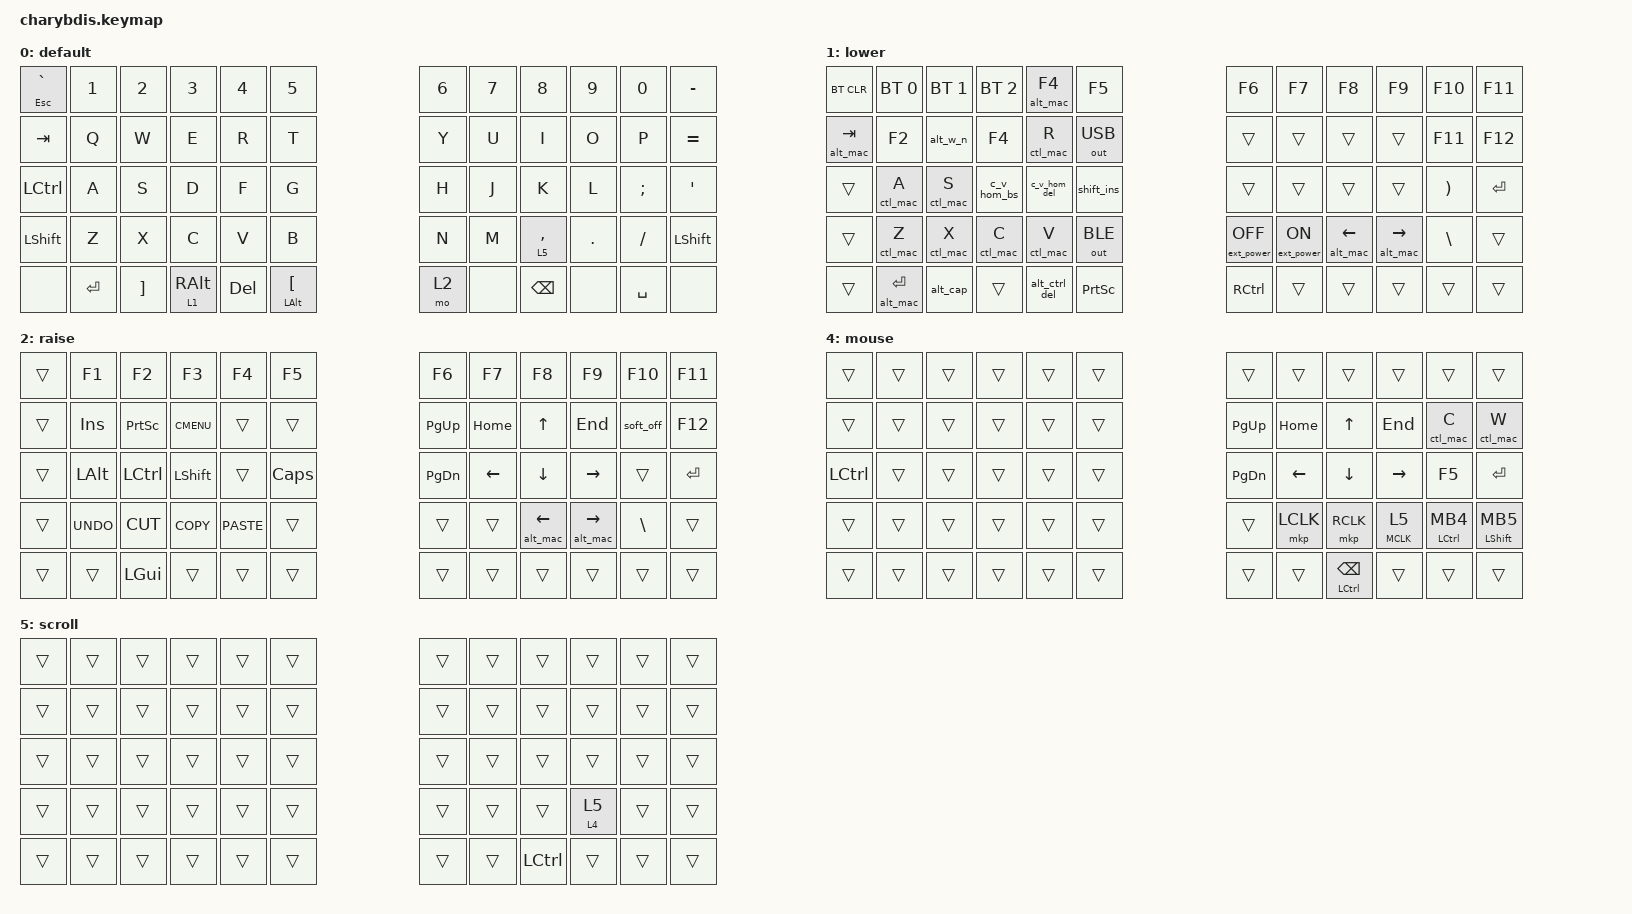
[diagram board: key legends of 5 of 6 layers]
/*
 * Copyright (c) 2020 The ZMK Contributors
 *
 * SPDX-License-Identifier: MIT
 */

#include <behaviors.dtsi>
#include <behaviors/mouse_key_press.dtsi>
#include <dt-bindings/zmk/keys.h>
#include <dt-bindings/zmk/bt.h>
#include <dt-bindings/zmk/rgb.h>
#include <dt-bindings/zmk/ext_power.h>
#include <dt-bindings/zmk/outputs.h>
#include <dt-bindings/zmk/mouse.h>

#define BASE 0
#define LOWER 1
#define RAISE 2
#define ADJUST 3
#define MOUSE 4
#define SCROLL 5

&soft_off {
    hold-time-ms = <3000>; // Only turn off it the key is held for 3 seconds or longer.
};

/ {
    macros {
        shift_ins: shift_ins {
            label = "ZM_shift_ins";
            compatible = "zmk,behavior-macro";
            #binding-cells = <0>;
            bindings
                = <&macro_press &kp LSHFT>
                , <&macro_tap &kp INS>
                , <&macro_release &kp LSHFT>
                ;
        };

        ctrl_back: ctrl_back {
            label = "ZM_ctrl_back";
            compatible = "zmk,behavior-macro";
            #binding-cells = <0>;
            bindings
                = <&macro_press &kp LCTRL> 
                , <&macro_tap &kp MINUS>
                , <&macro_release &kp LCTRL>
                ;
        };

        ctrl_sh_back: ctrl_sh_back {
            label = "ZM_ctrl_sh_back";
            compatible = "zmk,behavior-macro";
            #binding-cells = <0>;
            bindings
                = <&macro_press &kp LCTRL &kp LSHIFT>
                , <&macro_tap &kp MINUS>
                , <&macro_release &kp LCTRL &kp LSHIFT>
                ;
        };

        ctrl_tab: ctrl_tab {
            label = "ZM_ctrl_tab";
            compatible = "zmk,behavior-macro";
            #binding-cells = <0>;
            bindings
                = <&macro_press &kp LCTRL> 
                , <&macro_tap &kp TAB>
                , <&macro_release &kp LCTRL>
                ;
        };

        ctrl_sh_tab: ctrl_sh_tab {
            label = "ZM_ctrl_sh_tab";
            compatible = "zmk,behavior-macro";
            #binding-cells = <0>;
            bindings
                = <&macro_press &kp LCTRL &kp LSHIFT>
                , <&macro_tap &kp TAB>
                , <&macro_release &kp LCTRL &kp LSHIFT>
                ;
        };

        alt_ctrl_del: alt_ctrl_del {
            label = "ZM_alt_ctrl_del";
            compatible = "zmk,behavior-macro";
            #binding-cells = <0>;
            bindings
                = <&macro_press &kp LCTRL &kp LALT>
                , <&macro_tap &kp DEL>
                , <&macro_release &kp LCTRL &kp LALT>
                ;
        };

        alt_f4: alt_f4 {
            label = "ZM_alt_f4";
            compatible = "zmk,behavior-macro";
            #binding-cells = <0>;
            bindings
                = <&macro_press &kp LALT>
                , <&macro_tap &kp F4>
                , <&macro_release &kp LALT>
                ;
        };

        alt_cap: alt_cap {
            label = "ZM_alt_cap";
            compatible = "zmk,behavior-macro";
            #binding-cells = <0>;
            bindings
                = <&macro_press &kp LALT>
                , <&macro_tap &kp PSCRN>
                , <&macro_release &kp LALT>
                ;
        };

        alt_w_n: alt_w_n {
            label = "ZM_alt_w_n";
            compatible = "zmk,behavior-macro";
            #binding-cells = <0>;
            bindings
                = <&macro_press &kp LALT>
                , <&macro_tap &kp W &kp N>
                , <&macro_release &kp LALT>
                ;
        };

        c_v_hom_del: c_v_hom_del {
            label = "ZM_c_v_hom_del";
            compatible = "zmk,behavior-macro";
            #binding-cells = <0>;
            bindings
                = <&macro_press &kp LCTRL>
                , <&macro_tap &kp V>
                , <&macro_release &kp LCTRL>
                , <&macro_tap &kp HOME &kp RIGHT &kp BSPC>
                ;
        };

        c_v_hom_bs: c_v_hom_bs {
            label = "ZM_c_v_hom_bs";
            compatible = "zmk,behavior-macro";
            #binding-cells = <0>;
            bindings
                = <&macro_press &kp LCTRL>
                , <&macro_tap &kp V>
                , <&macro_release &kp LCTRL>
                , <&macro_tap &kp HOME &kp RIGHT &kp RIGHT &kp RIGHT>
                , <&macro_press &kp LSHFT>
                , <&macro_tap &kp END>
                , <&macro_release &kp LSHFT>
                , <&macro_tap &kp BSPC>
                ;
        };

       
    };

};




    

/ {
        hm: homerow_mods {
            compatible = "zmk,behavior-hold-tap";
            label = "HOMEROW_MODS";
            #binding-cells = <2>;
            tapping-term-ms = <200>;
            quick-tap-ms = <0>;
            flavor = "tap-preferred";
            bindings = <&kp>, <&kp>;
        };
        se: shift_enter {
            compatible = "zmk,behavior-hold-tap";
            label = "SHIFT_ENTER";
            #binding-cells = <2>;
            tapping-term-ms = <80>;
            quick-tap-ms = <0>;
            flavor = "tap-preferred";
            bindings = <&kp>, <&kp>;
        };
        al: alt_layer {
            compatible = "zmk,behavior-hold-tap";
            label = "ALT_LAYER";
            #binding-cells = <2>;
            tapping-term-ms = <136>;
            quick-tap-ms = <0>;
            flavor = "tap-preferred";
            bindings = <&mo>, <&kp>;
        };

        scl: scl_layer {
            compatible = "zmk,behavior-hold-tap";
            label = "SCL_LAYER";
            #binding-cells = <2>;
            tapping-term-ms = <200>;
            quick-tap-ms = <0>;
            flavor = "tap-preferred";
            bindings = <&mo>, <&tog>;
        };

        sclk: sclk_layer {
            compatible = "zmk,behavior-hold-tap";
            label = "SCLK_LAYER";
            #binding-cells = <2>;
            tapping-term-ms = <200>;
            quick-tap-ms = <0>;
            flavor = "tap-preferred";
            bindings = <&mkp>, <&tog>;
        };

        
        alt_mac:alt_mac {
            label="ALT_MACRO";
            compatible="zmk,behavior-macro-one-param";
            wait-ms=<0>;
            tap-ms=<0>;
            #binding-cells=<1>;
            bindings
                =<&macro_press &kp LALT>
                ,<&macro_param_1to1>
                ,<&macro_press &kp MACRO_PLACEHOLDER>
                ,<&macro_pause_for_release>
                ,<&macro_param_1to1>
                ,<&macro_release &kp MACRO_PLACEHOLDER>
                ,<&macro_release &kp LALT>
                ;
        };

        ctl_mac:ctr_mac {
            label="CTRL_MACRO";
            compatible="zmk,behavior-macro-one-param";
            wait-ms=<0>;
            tap-ms=<0>;
            #binding-cells=<1>;
            bindings
                =<&macro_press &kp LCTRL>
                ,<&macro_param_1to1>
                ,<&macro_press &kp MACRO_PLACEHOLDER>
                ,<&macro_pause_for_release>
                ,<&macro_param_1to1>
                ,<&macro_release &kp MACRO_PLACEHOLDER>
                ,<&macro_release &kp LCTRL>
                ;
        };

        alt_db:alt_db {
            compatible="zmk,behavior-hold-tap";
            label="ALT_DOUBLE";
            #binding-cells=<2>;
            flavor="tap-preferred";
            tapping-term-ms=<200>;
            quick-tap-ms=<135>;
            global-quick-tap;
            bindings=<&kp>,<&alt_mac>;
        };

        alt_db_second: alt_db_second {
            compatible = "zmk,behavior-hold-tap";
            label = "SCLK_LAYER_SECOND";
            #binding-cells = <2>;
            tapping-term-ms = <200>;
            quick-tap-ms = <0>;
            flavor = "tap-preferred";
            bindings = <&kp>, <&mkp>;
        };

        to_mac:to_mac {
            label="TO_MACRO";
            compatible="zmk,behavior-macro-one-param";
            wait-ms=<0>;
            tap-ms=<0>;
            #binding-cells=<1>;
            bindings
                =<&macro_press &to 0>
                ,<&macro_param_1to1>
                ,<&macro_press &kp MACRO_PLACEHOLDER>
                ,<&macro_pause_for_release>
                ,<&macro_param_1to1>
                ,<&macro_release &kp MACRO_PLACEHOLDER>
                ,<&macro_release &to 0>
                ;
        };

        alt_end:alt_end {
            compatible="zmk,behavior-hold-tap";
            label="ALT_END";
            #binding-cells=<2>;
            flavor="tap-preferred";
            tapping-term-ms=<170>;
            quick-tap-ms=<135>;
            global-quick-tap;
            bindings=<&to_mac>,<&alt_mac>;
        };

        alt_end_second:alt_end_second {
            compatible="zmk,behavior-hold-tap";
            label="ALT_END_SECOND";
            #binding-cells=<2>;
            flavor="tap-preferred";
            tapping-term-ms=<170>;
            quick-tap-ms=<135>;
            global-quick-tap;
            bindings=<&to_mac>,<&mkp>;
        };

        kp_end:kp_end {
            compatible="zmk,behavior-hold-tap";
            label="kp_END";
            #binding-cells=<2>;
            flavor="tap-preferred";
            tapping-term-ms=<200>;
            quick-tap-ms=<135>;
            global-quick-tap;
            bindings=<&kp>,<&to_mac>;
        };

        
 };

/ {

   // Activate ADJUST layer by pressing raise and lower
    conditional_layers {
        compatible = "zmk,conditional-layers";
        adjust_layer {
            if-layers = <LOWER RAISE>;
            then-layer = <ADJUST>;
        };
    };

    keymap {
        compatible = "zmk,keymap";

        default_layer {
            display-name = "default";
// ------------------------------------------------------------------------------------------------------------
// |   `   |  1  |  2  |  3   |  4   |  5   |                   |  6   |  7    |  8    |  9   |   0   |       |
// |  ESC  |  Q  |  W  |  E   |  R   |  T   |                   |  Y   |  U    |  I    |  O   |   P   | BKSPC |
// |  TAB  |  A  |  S  |  D   |  F   |  G   |                   |  H   |  J    |  K    |  L   |   ;   |   '   |
// | SHIFT |  Z  |  X  |  C   |  V   |  B   |  MUTE  |  |       |  N   |  M    |  ,    |  .   |   /   | SHIFT |
//               | GUI | ALT  | CTRL | LOWER|  ENTER |  | SPACE | RAISE| CTRL  | ALT   | GUI  |
            bindings = <
&hm ESC GRAVE  &kp N1  &kp N2   &kp N3     &kp N4   &kp N5                 &kp N6 &kp N7   &kp N8    &kp N9  &kp N0   &kp MINUS
&kp TAB        &kp Q   &kp W    &kp E      &kp R    &kp T                  &kp Y  &kp U    &kp I     &kp O   &kp P    &kp EQUAL
&kp LCTRL      &kp A   &kp S    &kp D      &kp F    &kp G                  &kp H  &kp J    &kp K     &kp L   &kp SEMI &kp SQT
&kp LSHFT      &kp Z   &kp X    &kp C      &kp V    &kp B                  &kp N  &kp M    &al 5 COMMA &kp DOT &kp FSLH &kp LSHFT
&none          &kp RET &kp RBKT &al 1 RALT &kp DEL  &hm LALT LBKT               &mo 2  &none    &kp BSPC  &none   &kp SPACE &none 
            >;
        };

        lower_layer {
            display-name = "lower";
// TODO: Some binds are waiting for shifted keycode support.
// ------------------------------------------------------------------------------------------------------------
// |       |  F1 |  F2 |  F3  |  F4  |  F5  |                   |  F6  |  F7   |  F8   |  F9  |  F10  |  F11  |
// |   `   |  1  |  2  |  3   |  4   |  5   |                   |  6   |  7    |  8    |  9   |   0   |  F12  |
// |       |  !  |  @  |  #   |  $   |  %   |                   |  ^   |  &    |  *    |  (   |   )   |   |   |
// |       |  =  |  -  |  +   |  {   |  }   |        |  |       |  [   |  ]    |  ;    |  :   |   \   |       |
//               |     |      |      |      |        |  |       |      |       |       |      |
            bindings = <
&bt BT_CLR &bt BT_SEL 0  &bt BT_SEL 1 &bt BT_SEL 2 &alt_mac F4    &kp F5                        &kp F6   &kp F7   &kp F8 &kp F9 &kp F10 &kp F11
&alt_mac TAB   &kp F2    &alt_w_n     &kp F4       &ctl_mac R     &out OUT_USB                  &trans   &trans   &trans &trans &kp F11 &kp F12
&trans     &ctl_mac A    &ctl_mac S   &c_v_hom_bs  &c_v_hom_del   &shift_ins                    &trans   &trans   &trans &trans &kp RPAR &kp RET
&trans     &ctl_mac Z    &ctl_mac X   &ctl_mac C   &ctl_mac V     &out OUT_BLE                  &ext_power EP_OFF &ext_power EP_ON &alt_mac LEFT  &alt_mac RIGHT  &kp BSLH  &trans
&trans     &alt_mac RET  &alt_cap     &trans       &alt_ctrl_del  &kp PSCRN                     &kp RCTRL  &trans    &trans   &trans  &trans  &trans
            >;
        };

        raise_layer {
            display-name = "raise";
// ------------------------------------------------------------------------------------------------------------
// | BTCLR | BT1  | BT2  |  BT3  |  BT4  |  BT5 |                |      |      |       |      |       |       |
// |       | INS  | PSCR | GUI   |       |      |                | PGUP |      |   ^   |      |       |       |
// |       | ALT  | CTRL | SHIFT |       | CAPS |                | PGDN |   <- |   v   |  ->  |  DEL  | BKSPC |
// |       | UNDO | CUT  | COPY  | PASTE |      |      |  |      |      |      |       |      |       |       |
//                |      |       |       |      |      |  |      |      |      |       |      |
            bindings = <
&trans     &kp F1       &kp F2       &kp F3       &kp F4       &kp F5                   &kp F6    &kp F7    &kp F8   &kp F9     &kp F10  &kp F11
&trans     &kp INS      &kp PSCRN    &kp K_CMENU  &trans       &trans                   &kp PG_UP &kp HOME  &kp UP   &kp END    &soft_off   &kp F12
&trans     &kp LALT     &kp LCTRL    &kp LSHFT    &trans       &kp CLCK                 &kp PG_DN &kp LEFT  &kp DOWN &kp RIGHT  &trans   &kp RET
&trans     &kp K_UNDO   &kp K_CUT    &kp K_COPY   &kp K_PASTE  &trans                   &trans    &trans    &alt_mac LEFT  &alt_mac RIGHT &kp BSLH &trans
&trans     &trans       &kp LGUI     &trans       &trans       &trans                   &trans    &trans    &trans   &trans     &trans   &trans
            >;

        };

        adjust_layer {
// ----------------------------------------------------------------------------------------------------------------------------
// | BTCLR  |  BT1    |  BT2    |   BT3   |   BT4   |   BT5   |                  |      |      |       |      |       |       |
// | EXTPWR | RGB_HUD | RGB_HUI | RGB_SAD | RGB_SAI | RGB_EFF |                  |      |      |       |      |       |       |
// |        | RGB_BRD | RGB_BRI |         |         |         |                  |      |      |       |      |       |       |
// |        |         |         |         |         |         | RGB_TOG | |      |      |      |       |      |       |       |
//                    |         |         |         |         |         | |      |      |      |       |      |
            display-name = "adjust";
            bindings = <
&bt BT_CLR        &bt BT_SEL 0    &bt BT_SEL 1    &bt BT_SEL 2    &bt BT_SEL 3    &bt BT_SEL 4                            &none &none &none &none &none &none
&ext_power EP_TOG &rgb_ug RGB_HUD &rgb_ug RGB_HUI &rgb_ug RGB_SAD &rgb_ug RGB_SAI &rgb_ug RGB_EFF                         &none &none &none &none &none &none
&none             &rgb_ug RGB_BRD &rgb_ug RGB_BRI &none           &none           &none                                   &none &none &none &none &none &none
&none             &none           &none           &none           &none           &none            &rgb_ug RGB_TOG &none  &none &none &none &none &none &none
&none             &none           &none           &none           &none           &none                                   &none &none &none &none &none &none
            >;
        };

        mouse_layer {
// ----------------------------------------------------------------------------------------------------------------------------
// | BTCLR  |  BT1    |  BT2    |   BT3   |   BT4   |   BT5   |                  |      |      |       |      |       |       |
// | EXTPWR | RGB_HUD | RGB_HUI | RGB_SAD | RGB_SAI | RGB_EFF |                  |      |      |       |      |       |       |
// |        | RGB_BRD | RGB_BRI |         |         |         |                  |      |      |       |      |       |       |
// |        |         |         |         |         |         | RGB_TOG | |      |      |      |       |      |       |       |
//                    |         |         |         |         |         | |      |      |      |       |      |
            display-name = "mouse";
            bindings = <
&trans  &trans  &trans  &trans  &trans  &trans                   &trans    &trans    &trans   &trans    &trans  &trans
&trans  &trans  &trans  &trans  &trans  &trans                   &kp PG_UP &kp HOME  &kp UP   &kp END   &ctl_mac C  &ctl_mac W
&kp LCTRL  &trans  &trans  &trans  &trans  &trans                &kp PG_DN &kp LEFT  &kp DOWN &kp RIGHT &kp F5 &kp RET
&trans  &trans  &trans  &trans  &trans  &trans                &trans    &mkp LCLK &mkp RCLK &sclk MCLK 5 &alt_db_second LCTRL MB4 &alt_end_second LSHIFT MB5
&trans  &trans  &trans  &trans  &trans  &trans                   &trans    &trans    &kp_end LCTRL BSPC &trans    &trans  &trans
            >;
        };

        scroll_layer {
// ----------------------------------------------------------------------------------------------------------------------------
// | BTCLR  |  BT1    |  BT2    |   BT3   |   BT4   |   BT5   |                  |      |      |       |      |       |       |
// | EXTPWR | RGB_HUD | RGB_HUI | RGB_SAD | RGB_SAI | RGB_EFF |                  |      |      |       |      |       |       |
// |        | RGB_BRD | RGB_BRI |         |         |         |                  |      |      |       |      |       |       |
// |        |         |         |         |         |         | RGB_TOG | |      |      |      |       |      |       |       |
//                    |         |         |         |         |         | |      |      |      |       |      |
            display-name = "scroll";
            bindings = <
&trans  &trans  &trans  &trans  &trans  &trans                   &trans    &trans    &trans   &trans    &trans  &trans
&trans  &trans  &trans  &trans  &trans  &trans                   &trans    &trans    &trans   &trans    &trans  &trans
&trans  &trans  &trans  &trans  &trans  &trans                   &trans    &trans    &trans   &trans    &trans  &trans
&trans  &trans  &trans  &trans  &trans  &trans                   &trans    &trans    &trans   &scl 4 5  &trans  &trans
&trans  &trans  &trans  &trans  &trans  &trans                   &trans    &trans    &kp LCTRL &trans    &trans  &trans
            >;
        };

    };
};
